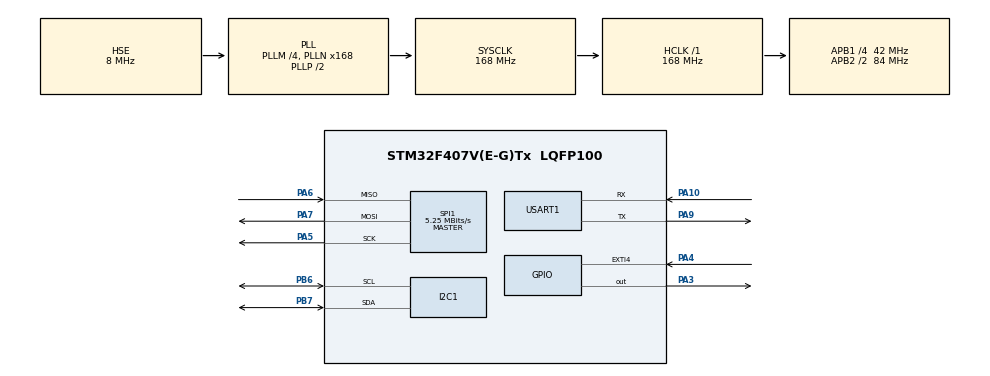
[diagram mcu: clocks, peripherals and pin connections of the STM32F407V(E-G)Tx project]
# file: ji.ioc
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FREERTOS.BinarySemaphores01=xx,Dynamic,NULL
FREERTOS.Tasks01=aTask,24,128,StartATask,Default,NULL,Dynamic,NULL,NULL;dTask,8,128,StartDTask,Default,NULL,Dynamic,NULL,NULL
I2C1.I2C_Mode=I2C_Fast
Mcu.Family=STM32F4
Mcu.Name=STM32F407V(E-G)Tx
Mcu.Package=LQFP100
NVIC.EXTI4_IRQn=true\:5\:0\:false\:false\:true\:true\:true\:true
NVIC.PriorityGroup=NVIC_PRIORITYGROUP_4
NVIC.TIM7_IRQn=true\:0\:0\:false\:false\:true\:false\:false\:true
NVIC.TimeBase=TIM7_IRQn
NVIC.TimeBaseIP=TIM7
PA10.Mode=Asynchronous
PA10.Signal=USART1_RX
PA3.Signal=GPIO_Output
PA4.GPIO_ModeDefaultEXTI=GPIO_MODE_IT_FALLING
PA4.Signal=GPXTI4
PA5.Mode=Full_Duplex_Master
PA5.Signal=SPI1_SCK
PA6.Mode=Full_Duplex_Master
PA6.Signal=SPI1_MISO
PA7.Mode=Full_Duplex_Master
PA7.Signal=SPI1_MOSI
PA9.Mode=Asynchronous
PA9.Signal=USART1_TX
PB6.Mode=I2C
PB6.Signal=I2C1_SCL
PB7.Mode=I2C
PB7.Signal=I2C1_SDA
PH0-OSC_IN.Mode=HSE-External-Oscillator
PH0-OSC_IN.Signal=RCC_OSC_IN
PH1-OSC_OUT.Mode=HSE-External-Oscillator
PH1-OSC_OUT.Signal=RCC_OSC_OUT
ProjectManager.HeapSize=0x600
ProjectManager.StackSize=0x600
ProjectManager.TargetToolchain=MDK-ARM V5.27
RCC.48MHZClocksFreq_Value=84000000
RCC.AHBFreq_Value=168000000
RCC.APB1CLKDivider=RCC_HCLK_DIV4
RCC.APB1Freq_Value=42000000
RCC.APB1TimFreq_Value=84000000
RCC.APB2CLKDivider=RCC_HCLK_DIV2
RCC.APB2Freq_Value=84000000
RCC.APB2TimFreq_Value=168000000
RCC.CortexFreq_Value=168000000
RCC.HCLKFreq_Value=168000000
RCC.HSE_VALUE=8000000
RCC.HSI_VALUE=16000000
RCC.LSE_VALUE=32768
RCC.PLLM=4
RCC.PLLN=168
RCC.PLLSourceVirtual=RCC_PLLSOURCE_HSE
RCC.SYSCLKFreq_VALUE=168000000
RCC.SYSCLKSource=RCC_SYSCLKSOURCE_PLLCLK
RCC.VCOOutputFreq_Value=336000000
SPI1.BaudRatePrescaler=SPI_BAUDRATEPRESCALER_16
SPI1.CalculateBaudRate=5.25 MBits/s
SPI1.Direction=SPI_DIRECTION_2LINES
SPI1.Mode=SPI_MODE_MASTER
SPI1.VirtualType=VM_MASTER
USART1.VirtualMode=VM_ASYNC
VP_FREERTOS_VS_CMSIS_V2.Mode=CMSIS_V2
VP_SYS_VS_tim7.Mode=TIM7
board=custom

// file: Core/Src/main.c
/* USER CODE BEGIN Header */
/**
  ******************************************************************************
  * @file           : main.c
  * @brief          : Main program body
  ******************************************************************************
  * @attention
  *
  * <h2><center>&copy; Copyright (c) 2021 STMicroelectronics.
  * All rights reserved.</center></h2>
  *
  * This software component is licensed by ST under BSD 3-Clause license,
  * the "License"; You may not use this file except in compliance with the
  * License. You may obtain a copy of the License at:
  *                        opensource.org/licenses/BSD-3-Clause
  *
  ******************************************************************************
  */
/* USER CODE END Header */
#include "main.h"
#include "cmsis_os.h"
#include "i2c.h"
#include "spi.h"
#include "usart.h"
#include "gpio.h"

/* USER CODE BEGIN PD */
uint8_t u_buf[256];
/* USER CODE END PD */

void SystemClock_Config(void);
void MX_FREERTOS_Init(void);

int main(void)
{

  /* MCU Configuration--------------------------------------------------------*/

  /* Reset of all peripherals, Initializes the Flash interface and the Systick. */
  HAL_Init();

  /* Configure the system clock */
  SystemClock_Config();

  /* Initialize all configured peripherals */
  MX_GPIO_Init();
  MX_USART1_UART_Init();
  MX_I2C1_Init();
  MX_SPI1_Init();
  /* USER CODE BEGIN 2 */
int x=235555554;
  /* USER CODE END 2 */

  /* Init scheduler */
  osKernelInitialize();  /* Call init function for freertos objects (in freertos.c) */
  MX_FREERTOS_Init();
  /* Start scheduler */
  osKernelStart();

  /* We should never get here as control is now taken by the scheduler */
  /* Infinite loop */
  /* USER CODE BEGIN WHILE */
  while (1)
  {
		printf("fuckfghhhhhhhhhh      %d\n",x);
		HAL_Delay(1000);
    /* USER CODE END WHILE */

  }
}

void SystemClock_Config(void)
{
  RCC_OscInitTypeDef RCC_OscInitStruct = {0};
  RCC_ClkInitTypeDef RCC_ClkInitStruct = {0};

  /** Configure the main internal regulator output voltage
  */
  __HAL_RCC_PWR_CLK_ENABLE();
  __HAL_PWR_VOLTAGESCALING_CONFIG(PWR_REGULATOR_VOLTAGE_SCALE1);
  /** Initializes the RCC Oscillators according to the specified parameters
  * in the RCC_OscInitTypeDef structure.
  */
  RCC_OscInitStruct.OscillatorType = RCC_OSCILLATORTYPE_HSE;
  RCC_OscInitStruct.HSEState = RCC_HSE_ON;
  RCC_OscInitStruct.PLL.PLLState = RCC_PLL_ON;
  RCC_OscInitStruct.PLL.PLLSource = RCC_PLLSOURCE_HSE;
  RCC_OscInitStruct.PLL.PLLM = 4;
  RCC_OscInitStruct.PLL.PLLN = 168;
  RCC_OscInitStruct.PLL.PLLP = RCC_PLLP_DIV2;
  RCC_OscInitStruct.PLL.PLLQ = 4;
  if (HAL_RCC_OscConfig(&RCC_OscInitStruct) != HAL_OK)
  {
    Error_Handler();
  }
  /** Initializes the CPU, AHB and APB buses clocks
  */
  RCC_ClkInitStruct.ClockType = RCC_CLOCKTYPE_HCLK|RCC_CLOCKTYPE_SYSCLK
                              |RCC_CLOCKTYPE_PCLK1|RCC_CLOCKTYPE_PCLK2;
  RCC_ClkInitStruct.SYSCLKSource = RCC_SYSCLKSOURCE_PLLCLK;
  RCC_ClkInitStruct.AHBCLKDivider = RCC_SYSCLK_DIV1;
  RCC_ClkInitStruct.APB1CLKDivider = RCC_HCLK_DIV4;
  RCC_ClkInitStruct.APB2CLKDivider = RCC_HCLK_DIV2;

  if (HAL_RCC_ClockConfig(&RCC_ClkInitStruct, FLASH_LATENCY_5) != HAL_OK)
  {
    Error_Handler();
  }
}

 /**
  * @brief  Period elapsed callback in non blocking mode
  * @note   This function is called  when TIM7 interrupt took place, inside
  * HAL_TIM_IRQHandler(). It makes a direct call to HAL_IncTick() to increment
  * a global variable "uwTick" used as application time base.
  * @param  htim : TIM handle
  * @retval None
  */
void HAL_TIM_PeriodElapsedCallback(TIM_HandleTypeDef *htim)
{
  if (htim->Instance == TIM7) {
    HAL_IncTick();
  }
}

void Error_Handler(void)
{
  __disable_irq();
  while (1)
  {
  }
}

/************************ (C) COPYRIGHT STMicroelectronics *****END OF FILE****/

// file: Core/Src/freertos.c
/* USER CODE BEGIN Header */
/**
  ******************************************************************************
  * File Name          : freertos.c
  * Description        : Code for freertos applications
  ******************************************************************************
  * @attention
  *
  * <h2><center>&copy; Copyright (c) 2021 STMicroelectronics.
  * All rights reserved.</center></h2>
  *
  * This software component is licensed by ST under Ultimate Liberty license
  * SLA0044, the "License"; You may not use this file except in compliance with
  * the License. You may obtain a copy of the License at:
  *                             www.st.com/SLA0044
  *
  ******************************************************************************
  */
/* USER CODE END Header */

#include "FreeRTOS.h"
#include "task.h"
#include "main.h"
#include "cmsis_os.h"

/* Definitions for aTask */
osThreadId_t aTaskHandle;
const osThreadAttr_t aTask_attributes = {
  .name = "aTask",
  .stack_size = 128 * 4,
  .priority = (osPriority_t) osPriorityNormal,
};
/* Definitions for dTask */
osThreadId_t dTaskHandle;
const osThreadAttr_t dTask_attributes = {
  .name = "dTask",
  .stack_size = 128 * 4,
  .priority = (osPriority_t) osPriorityLow,
};
/* Definitions for xx */
osSemaphoreId_t xxHandle;
const osSemaphoreAttr_t xx_attributes = {
  .name = "xx"
};

void StartATask(void *argument);
void StartDTask(void *argument);

void MX_FREERTOS_Init(void); /* (MISRA C 2004 rule 8.1) */

void MX_FREERTOS_Init(void) {

  /* Create the semaphores(s) */
  /* creation of xx */
  xxHandle = osSemaphoreNew(1, 1, &xx_attributes);

  /* Create the thread(s) */
  /* creation of aTask */
  aTaskHandle = osThreadNew(StartATask, NULL, &aTask_attributes);

  /* creation of dTask */
  dTaskHandle = osThreadNew(StartDTask, NULL, &dTask_attributes);

}

void StartATask(void *argument)
{
  for(;;)
  {
    osDelay(1);
  }
}

void StartDTask(void *argument)
{
  for(;;)
  {
    osDelay(1);
  }
}

/************************ (C) COPYRIGHT STMicroelectronics *****END OF FILE****/
